AUTOSAR XML
package /EvSwcs
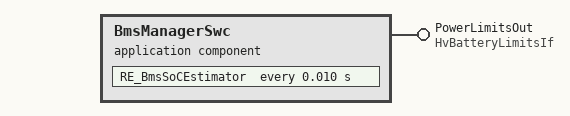
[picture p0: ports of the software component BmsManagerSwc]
  application sw component type BmsManagerSwc
    provide port PowerLimitsOut: provided-interface=HvBatteryLimitsIf
    behavior BmsManager_IB
      runnable RE_BmsSoCEstimator: execution-time-wcet=0.0025
      timing event TE_Bms_10ms: start-on-event=RE_BmsSoCEstimator, period=0.010
